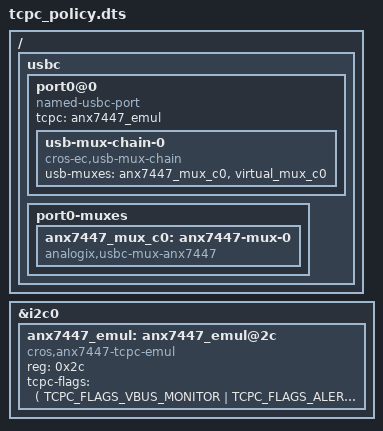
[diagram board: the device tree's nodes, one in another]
/* Copyright 2022 The ChromiumOS Authors
 * Use of this source code is governed by a BSD-style license that can be
 * found in the LICENSE file.
 */

#include <dt-bindings/usb_pd_tcpm.h>

/ {
	usbc {
		port0@0 {
			compatible = "named-usbc-port";
			tcpc = <&anx7447_emul>;
			usb-mux-chain-0 {
				compatible = "cros-ec,usb-mux-chain";
				usb-muxes = <&anx7447_mux_c0 &virtual_mux_c0>;
			};
		};
		port0-muxes {
			anx7447_mux_c0: anx7447-mux-0 {
				compatible = "analogix,usbc-mux-anx7447";
			};
		};
	};
};

&i2c0 {
	status="okay";

	anx7447_emul: anx7447_emul@2c {
		compatible = "cros,anx7447-tcpc-emul";
		reg = <0x2c>;
		tcpc-flags = <(
			TCPC_FLAGS_VBUS_MONITOR |
			TCPC_FLAGS_ALERT_OD |
			TCPC_FLAGS_CONTROL_VCONN |
			TCPC_FLAGS_CONTROL_FRS)>;
	};
};

